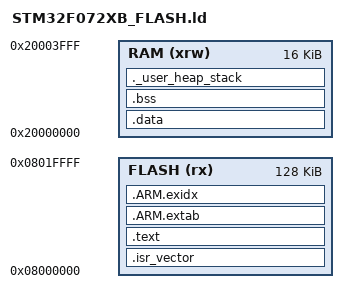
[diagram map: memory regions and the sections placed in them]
/* STM32F072xB: 128K FLASH, 16K RAM */
ENTRY(Reset_Handler)

MEMORY
{
    FLASH (rx)  : ORIGIN = 0x08000000, LENGTH = 128K
    RAM (xrw)   : ORIGIN = 0x20000000, LENGTH = 16K
}

_estack = ORIGIN(RAM) + LENGTH(RAM);

SECTIONS
{
    .isr_vector :
    {
        KEEP(*(.isr_vector))
    } > FLASH

    .text :
    {
        *(.text*)
        *(.rodata*)
        *(.glue_7)
        *(.glue_7t)
        KEEP(*(.init))
        KEEP(*(.fini))
        _etext = .;
    } > FLASH

    .ARM.extab : { *(.ARM.extab* .gnu.linkonce.armextab.*) } > FLASH
    .ARM.exidx : { *(.ARM.exidx* .gnu.linkonce.armexidx.*) } > FLASH

    _sidata = _etext;

    .data : AT(_sidata)
    {
        _sdata = .;
        *(.data*)
        _edata = .;
    } > RAM

    .bss :
    {
        _sbss = .;
        *(.bss*)
        *(COMMON)
        _ebss = .;
    } > RAM

    ._user_heap_stack :
    {
        . = ALIGN(8);
        PROVIDE(end = .);
        PROVIDE(_end = .);
        . = . + 0x400;
        . = . + 0x400;
        . = ALIGN(8);
    } > RAM
}
